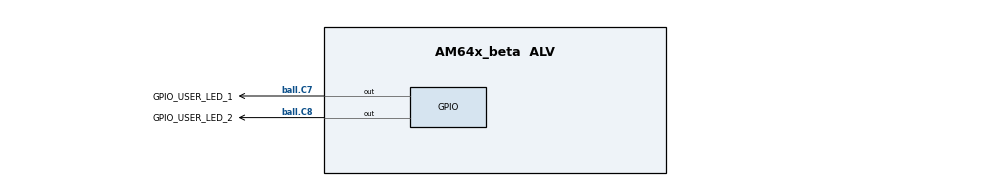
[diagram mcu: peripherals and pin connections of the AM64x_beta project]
/**
 * These arguments were used when this file was generated. They will be automatically applied on subsequent loads
 * via the GUI or CLI. Run CLI with '--help' for additional information on how to override these arguments.
 * @cliArgs --device "AM64x_beta" --package "ALV" --part "Default" --context "r5fss0-0" --product "MCU_PLUS_SDK_AM64x@08.02.00"
 * @versions {"tool":"1.12.1+2446"}
 */

/**
 * Import the modules used in this configuration.
 */
const ddr        = scripting.addModule("/drivers/ddr/ddr", {}, false);
const ddr1       = ddr.addInstance();
const gpio       = scripting.addModule("/drivers/gpio/gpio", {}, false);
const gpio1      = gpio.addInstance();
const gpio2      = gpio.addInstance();
const i2c        = scripting.addModule("/drivers/i2c/i2c", {}, false);
const i2c1       = i2c.addInstance();
const mcan       = scripting.addModule("/drivers/mcan/mcan", {}, false);
const mcan1      = mcan.addInstance();
const mcan2      = mcan.addInstance();
const mmcsd      = scripting.addModule("/drivers/mmcsd/mmcsd", {}, false);
const mmcsd1     = mmcsd.addInstance();
const ospi       = scripting.addModule("/drivers/ospi/ospi", {}, false);
const ospi1      = ospi.addInstance();
const uart       = scripting.addModule("/drivers/uart/uart", {}, false);
const uart1      = uart.addInstance();
const debug_log  = scripting.addModule("/kernel/dpl/debug_log");
const mpu_armv7  = scripting.addModule("/kernel/dpl/mpu_armv7", {}, false);
const mpu_armv71 = mpu_armv7.addInstance();
const mpu_armv72 = mpu_armv7.addInstance();
const mpu_armv73 = mpu_armv7.addInstance();
const mpu_armv74 = mpu_armv7.addInstance();
const mpu_armv75 = mpu_armv7.addInstance();
const mpu_armv76 = mpu_armv7.addInstance();

/**
 * Write custom configuration values to the imported modules.
 */
ddr1.$name                    = "CONFIG_DDR0";
ddr1.ddrConfigIncludeFileName = "C:/ti/mcu_plus_sdk_am64x_08_02_00_31/source/drivers/board_ddrReginit.h";

gpio1.pinDir                   = "OUTPUT";
gpio1.useMcuDomainPeripherals  = true;
gpio1.$name                    = "GPIO_USER_LED_1";
gpio1.MCU_GPIO.$assign         = "MCU_GPIO0";
gpio1.MCU_GPIO.gpioPin.$assign = "ball.C7";

gpio2.$name                    = "GPIO_USER_LED_2";
gpio2.pinDir                   = "OUTPUT";
gpio2.useMcuDomainPeripherals  = true;
gpio2.MCU_GPIO.gpioPin.$assign = "ball.C8";

i2c1.$name       = "CONFIG_I2C0";
i2c1.I2C.$assign = "I2C0";

mcan1.$name        = "CONFIG_MCAN0";
mcan1.MCAN.$assign = "MCAN0";

mcan2.$name        = "CONFIG_MCAN1";
mcan2.MCAN.$assign = "MCAN1";

mmcsd1.$name = "CONFIG_MMCSD0";

ospi1.$name        = "CONFIG_OSPI0";
ospi1.xferLines    = "QUAD";
ospi1.inputClkFreq = 83333333;

uart1.$name            = "CONFIG_USART0";
uart1.intrEnable       = "DISABLE";
uart1.UART.$assign     = "USART0";
uart1.UART.RXD.$assign = "ball.D15";
uart1.UART.TXD.$assign = "ball.C16";

mpu_armv71.$name             = "CONFIG_MPU_REGION0";
mpu_armv71.size              = 31;
mpu_armv71.attributes        = "Device";
mpu_armv71.accessPermissions = "Supervisor RD+WR, User RD";
mpu_armv71.allowExecute      = false;

mpu_armv72.$name             = "CONFIG_MPU_REGION1";
mpu_armv72.size              = 15;
mpu_armv72.accessPermissions = "Supervisor RD+WR, User RD";

mpu_armv73.$name             = "CONFIG_MPU_REGION2";
mpu_armv73.baseAddr          = 0x41010000;
mpu_armv73.size              = 15;
mpu_armv73.accessPermissions = "Supervisor RD+WR, User RD";

mpu_armv74.$name             = "CONFIG_MPU_REGION3";
mpu_armv74.baseAddr          = 0x70000000;
mpu_armv74.size              = 21;
mpu_armv74.accessPermissions = "Supervisor RD+WR, User RD";

mpu_armv75.$name             = "CONFIG_MPU_REGION4";
mpu_armv75.baseAddr          = 0x60000000;
mpu_armv75.size              = 28;
mpu_armv75.accessPermissions = "Supervisor RD, User RD";

mpu_armv76.$name    = "CONFIG_MPU_REGION5";
mpu_armv76.baseAddr = 0x80000000;
mpu_armv76.size     = 31;

/**
 * Pinmux solution for unlocked pins/peripherals. This ensures that minor changes to the automatic solver in a future
 * version of the tool will not impact the pinmux you originally saw.  These lines can be completely deleted in order to
 * re-solve from scratch.
 */
gpio2.MCU_GPIO.$suggestSolution  = "MCU_GPIO0";
i2c1.I2C.SCL.$suggestSolution    = "ball.A18";
i2c1.I2C.SDA.$suggestSolution    = "ball.B18";
mcan1.MCAN.RX.$suggestSolution   = "ball.B17";
mcan1.MCAN.TX.$suggestSolution   = "ball.A17";
mcan2.MCAN.RX.$suggestSolution   = "ball.D17";
mcan2.MCAN.TX.$suggestSolution   = "ball.C17";
mmcsd1.MMC0.$suggestSolution     = "MMC0";
ospi1.OSPI.$suggestSolution      = "OSPI0";
ospi1.OSPI.CLK.$suggestSolution  = "ball.N20";
ospi1.OSPI.CSn0.$suggestSolution = "ball.L19";
ospi1.OSPI.D3.$suggestSolution   = "ball.M21";
ospi1.OSPI.D2.$suggestSolution   = "ball.M20";
ospi1.OSPI.D1.$suggestSolution   = "ball.M18";
ospi1.OSPI.D0.$suggestSolution   = "ball.M19";
